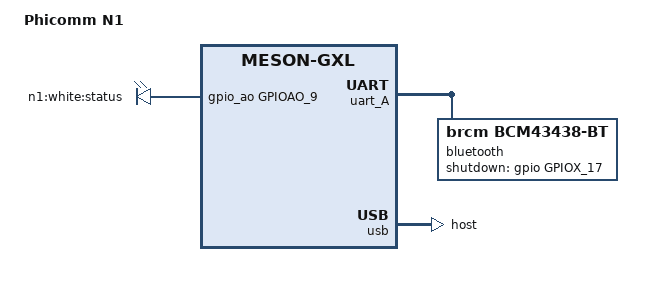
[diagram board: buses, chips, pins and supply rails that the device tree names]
// SPDX-License-Identifier: (GPL-2.0+ OR MIT)
/*
 * Copyright (c) 2018 He Yangxuan
 */

/dts-v1/;

#include "meson-gxl-s905d-p230.dts"

/ {
	compatible = "phicomm,n1", "amlogic,s905d", "amlogic,meson-gxl";
	model = "Phicomm N1";

	cvbs-connector {
		status = "disabled";
	};

	leds {
		compatible = "gpio-leds";

		led {
			label = "n1:white:status";
			gpios = <&gpio_ao GPIOAO_9 GPIO_ACTIVE_HIGH>;
			default-state = "on";
		};
	};
};

&cvbs_vdac_port {
	status = "disabled";
};

&uart_A {
	status = "okay";
	pinctrl-0 = <&uart_a_pins>, <&uart_a_cts_rts_pins>;
	pinctrl-names = "default";
	uart-has-rtscts;

	bluetooth {
		compatible = "brcm,bcm43438-bt";
		shutdown-gpios = <&gpio GPIOX_17 GPIO_ACTIVE_HIGH>;
		max-speed = <2000000>;
		clocks = <&wifi32k>;
		clock-names = "lpo";
	};
};

&usb {
	dr_mode = "host";
};
